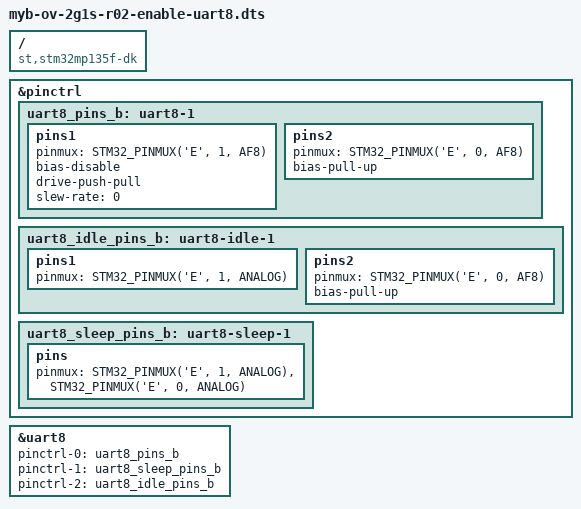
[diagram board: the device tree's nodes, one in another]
/dts-v1/;
/plugin/;

#include <dt-bindings/gpio/gpio.h>
#include <dt-bindings/pinctrl/stm32-pinfunc.h>

/ {
    compatible = "st,stm32mp135f-dk", "st,stm32mp135";

    fragment@0 {
        target = <&pinctrl>;
        __overlay__ {
            uart8_pins_b: uart8-1 {
                pins1 {
                    pinmux = <STM32_PINMUX('E', 1, AF8)>; /* UART8_TX (122) */
                    bias-disable;
                    drive-push-pull;
                    slew-rate = <0>;
                };
                pins2 {
                    pinmux = <STM32_PINMUX('E', 0, AF8)>; /* UART8_RX (146) */
                    bias-pull-up;
                };
            };

            uart8_idle_pins_b: uart8-idle-1 {
                pins1 {
                    pinmux = <STM32_PINMUX('E', 1, ANALOG)>; /* UART8_TX (122) */
                };
                pins2 {
                    pinmux = <STM32_PINMUX('E', 0, AF8)>; /* UART8_RX (146) */
                    bias-pull-up;
                };
            };

            uart8_sleep_pins_b: uart8-sleep-1 {
                pins {
                    pinmux = <STM32_PINMUX('E', 1, ANALOG)>, /* UART8_TX (122) */
                        <STM32_PINMUX('E', 0, ANALOG)>; /* UART8_RX (146) */
                };
            };
        };
    };

    fragment@1 {
        target = <&uart8>;
        __overlay__ {
            pinctrl-names = "default", "sleep", "idle";
            pinctrl-0 = <&uart8_pins_b>;
            pinctrl-1 = <&uart8_sleep_pins_b>;
            pinctrl-2 = <&uart8_idle_pins_b>;
            status = "okay";
        };
    };
};
